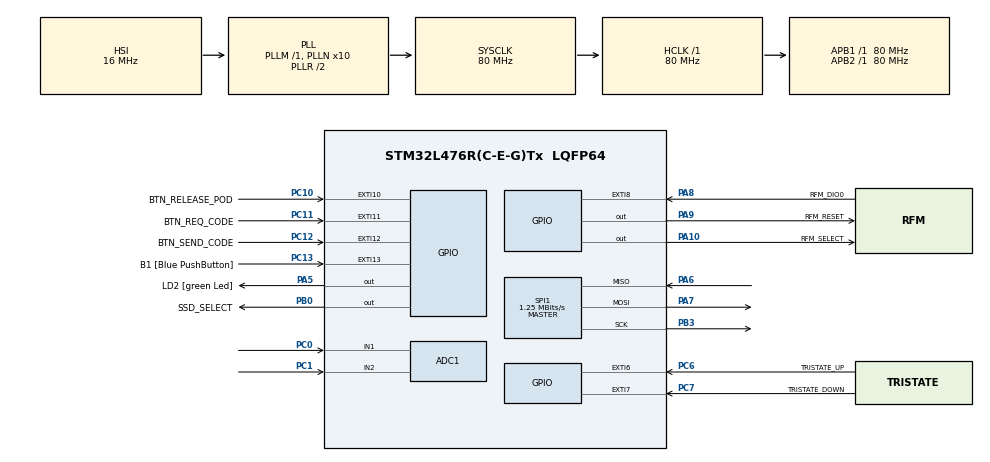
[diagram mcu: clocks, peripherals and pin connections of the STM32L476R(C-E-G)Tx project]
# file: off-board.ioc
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ADC1.Channel-0\#ChannelRegularConversion=ADC_CHANNEL_1
ADC1.Channel-1\#ChannelRegularConversion=ADC_CHANNEL_2
ADC1.ContinuousConvMode=DISABLE
ADC1.DMAContinuousRequests=DISABLE
ADC1.NbrOfConversion=2
ADC1.NbrOfConversionFlag=1
ADC1.OffsetNumber-0\#ChannelRegularConversion=ADC_OFFSET_NONE
ADC1.OffsetNumber-1\#ChannelRegularConversion=ADC_OFFSET_NONE
ADC1.Rank-0\#ChannelRegularConversion=1
ADC1.Rank-1\#ChannelRegularConversion=2
ADC1.SamplingTime-0\#ChannelRegularConversion=ADC_SAMPLETIME_2CYCLES_5
ADC1.SamplingTime-1\#ChannelRegularConversion=ADC_SAMPLETIME_2CYCLES_5
ADC1.master=1
Dma.ADC1.0.Direction=DMA_PERIPH_TO_MEMORY
Dma.ADC1.0.Instance=DMA1_Channel1
Dma.ADC1.0.MemDataAlignment=DMA_MDATAALIGN_HALFWORD
Dma.ADC1.0.MemInc=DMA_MINC_ENABLE
Dma.ADC1.0.Mode=DMA_NORMAL
Dma.ADC1.0.PeriphDataAlignment=DMA_PDATAALIGN_HALFWORD
Dma.ADC1.0.PeriphInc=DMA_PINC_DISABLE
Dma.ADC1.0.Priority=DMA_PRIORITY_HIGH
Dma.Request0=ADC1
Mcu.Family=STM32L4
Mcu.Name=STM32L476R(C-E-G)Tx
Mcu.Package=LQFP64
NVIC.ADC1_2_IRQn=true\:0\:0\:false\:false\:true\:true\:true\:true
NVIC.DMA1_Channel1_IRQn=true\:0\:0\:false\:false\:true\:false\:true\:true
NVIC.EXTI15_10_IRQn=true\:0\:0\:false\:false\:true\:true\:true\:true
NVIC.EXTI9_5_IRQn=true\:0\:0\:false\:false\:true\:true\:true\:true
NVIC.PriorityGroup=NVIC_PRIORITYGROUP_4
NVIC.SPI1_IRQn=true\:0\:0\:false\:false\:true\:true\:true\:true
NVIC.TIM6_DAC_IRQn=true\:0\:0\:false\:false\:true\:true\:true\:true
NVIC.TIM7_IRQn=true\:0\:0\:false\:false\:true\:true\:true\:true
PA10.GPIO_Label=RFM_SELECT
PA10.Signal=GPIO_Output
PA13\ (JTMS-SWDIO).Mode=Serial_Wire
PA13\ (JTMS-SWDIO).Signal=SYS_JTMS-SWDIO
PA14\ (JTCK-SWCLK).Mode=Serial_Wire
PA14\ (JTCK-SWCLK).Signal=SYS_JTCK-SWCLK
PA5.GPIO_Label=LD2 [green Led]
PA5.GPIO_ModeDefaultOutputPP=GPIO_MODE_OUTPUT_PP
PA5.GPIO_PuPd=GPIO_NOPULL
PA5.GPIO_Speed=GPIO_SPEED_FREQ_LOW
PA5.Signal=GPIO_Output
PA6.Mode=Full_Duplex_Master
PA6.Signal=SPI1_MISO
PA7.Mode=Full_Duplex_Master
PA7.Signal=SPI1_MOSI
PA8.GPIO_Label=RFM_DIO0
PA8.Signal=GPXTI8
PA9.GPIO_Label=RFM_RESET
PA9.Signal=GPIO_Output
PB0.GPIO_Label=SSD_SELECT
PB0.Signal=GPIO_Output
PB3\ (JTDO-TRACESWO).Mode=Full_Duplex_Master
PB3\ (JTDO-TRACESWO).Signal=SPI1_SCK
PC0.Signal=SharedAnalog_PC0
PC1.Signal=SharedAnalog_PC1
PC10.GPIO_Label=BTN_RELEASE_POD
PC10.GPIO_ModeDefaultEXTI=GPIO_MODE_IT_FALLING
PC10.GPIO_PuPd=GPIO_PULLDOWN
PC10.Signal=GPXTI10
PC11.GPIO_Label=BTN_REQ_CODE
PC11.GPIO_ModeDefaultEXTI=GPIO_MODE_IT_FALLING
PC11.GPIO_PuPd=GPIO_PULLDOWN
PC11.Signal=GPXTI11
PC12.GPIO_Label=BTN_SEND_CODE
PC12.GPIO_ModeDefaultEXTI=GPIO_MODE_IT_FALLING
PC12.GPIO_PuPd=GPIO_PULLDOWN
PC12.Signal=GPXTI12
PC13.GPIO_Label=B1 [Blue PushButton]
PC13.GPIO_ModeDefaultEXTI=GPIO_MODE_IT_FALLING
PC13.GPIO_PuPd=GPIO_NOPULL
PC13.Signal=GPXTI13
PC6.GPIO_Label=TRISTATE_UP
PC6.GPIO_PuPd=GPIO_PULLDOWN
PC6.Signal=GPXTI6
PC7.GPIO_Label=TRISTATE_DOWN
PC7.GPIO_PuPd=GPIO_PULLDOWN
PC7.Signal=GPXTI7
ProjectManager.HeapSize=0x200
ProjectManager.StackSize=0x400
ProjectManager.TargetToolchain=STM32CubeIDE
RCC.ADCFreq_Value=64000000
RCC.AHBFreq_Value=80000000
RCC.APB1Freq_Value=80000000
RCC.APB1TimFreq_Value=80000000
RCC.APB2Freq_Value=80000000
RCC.APB2TimFreq_Value=80000000
RCC.CortexFreq_Value=80000000
RCC.HCLKFreq_Value=80000000
RCC.HSE_VALUE=8000000
RCC.HSI_VALUE=16000000
RCC.LSE_VALUE=32768
RCC.MSI_VALUE=4000000
RCC.PLLN=10
RCC.PLLSourceVirtual=RCC_PLLSOURCE_HSI
RCC.PREFETCH_ENABLE=1
RCC.SYSCLKFreq_VALUE=80000000
RCC.SYSCLKSource=RCC_SYSCLKSOURCE_PLLCLK
RCC.USBFreq_Value=64000000
RCC.VCOOutputFreq_Value=160000000
SH.SharedAnalog_PC0.0=GPIO_Analog
SH.SharedAnalog_PC0.1=ADC1_IN1,IN1-Single-Ended
SH.SharedAnalog_PC1.0=GPIO_Analog
SH.SharedAnalog_PC1.1=ADC1_IN2,IN2-Single-Ended
SPI1.BaudRatePrescaler=SPI_BAUDRATEPRESCALER_64
SPI1.CalculateBaudRate=1.25 MBits/s
SPI1.DataSize=SPI_DATASIZE_8BIT
SPI1.Direction=SPI_DIRECTION_2LINES
SPI1.Mode=SPI_MODE_MASTER
SPI1.NSSPMode=SPI_NSS_PULSE_DISABLE
SPI1.VirtualType=VM_MASTER
TIM6.AutoReloadPreload=TIM_AUTORELOAD_PRELOAD_ENABLE
TIM6.Period=62499
TIM6.Prescaler=319
TIM7.AutoReloadPreload=TIM_AUTORELOAD_PRELOAD_ENABLE
TIM7.Period=49999
TIM7.Prescaler=159
VP_TIM6_VS_ClockSourceINT.Mode=Enable_Timer
VP_TIM7_VS_ClockSourceINT.Mode=Enable_Timer
board=NUCLEO-L476RG

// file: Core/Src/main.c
/* USER CODE BEGIN Header */
/**
  ******************************************************************************
  * @file           : main.c
  * @brief          : Main program body
  ******************************************************************************
  * @attention
  *
  * Copyright (c) 2024 STMicroelectronics.
  * All rights reserved.
  *
  * This software is licensed under terms that can be found in the LICENSE file
  * in the root directory of this software component.
  * If no LICENSE file comes with this software, it is provided AS-IS.
  *
  ******************************************************************************
  */
/* USER CODE END Header */
#include "main.h"

/* USER CODE BEGIN Includes */
#include "Custom/main.h"
/* USER CODE END Includes */

ADC_HandleTypeDef hadc1;
DMA_HandleTypeDef hdma_adc1;

SPI_HandleTypeDef hspi1;

TIM_HandleTypeDef htim6;
TIM_HandleTypeDef htim7;

void SystemClock_Config(void);
static void MX_GPIO_Init(void);
static void MX_DMA_Init(void);
static void MX_ADC1_Init(void);
static void MX_SPI1_Init(void);
static void MX_TIM7_Init(void);
static void MX_TIM6_Init(void);

int main(void)
{

  /* MCU Configuration--------------------------------------------------------*/

  /* Reset of all peripherals, Initializes the Flash interface and the Systick. */
  HAL_Init();

  /* Configure the system clock */
  SystemClock_Config();

  /* Initialize all configured peripherals */
  MX_GPIO_Init();
  MX_DMA_Init();
  MX_ADC1_Init();
  MX_SPI1_Init();
  MX_TIM7_Init();
  MX_TIM6_Init();
  /* USER CODE BEGIN 2 */
  setup();
  /* USER CODE END 2 */

  /* Infinite loop */
  /* USER CODE BEGIN WHILE */
  while (1)
  {
    loop();
    /* USER CODE END WHILE */

  }
}

void SystemClock_Config(void)
{
  RCC_OscInitTypeDef RCC_OscInitStruct = {0};
  RCC_ClkInitTypeDef RCC_ClkInitStruct = {0};

  /** Configure the main internal regulator output voltage
  */
  if (HAL_PWREx_ControlVoltageScaling(PWR_REGULATOR_VOLTAGE_SCALE1) != HAL_OK)
  {
    Error_Handler();
  }

  /** Initializes the RCC Oscillators according to the specified parameters
  * in the RCC_OscInitTypeDef structure.
  */
  RCC_OscInitStruct.OscillatorType = RCC_OSCILLATORTYPE_HSI;
  RCC_OscInitStruct.HSIState = RCC_HSI_ON;
  RCC_OscInitStruct.HSICalibrationValue = RCC_HSICALIBRATION_DEFAULT;
  RCC_OscInitStruct.PLL.PLLState = RCC_PLL_ON;
  RCC_OscInitStruct.PLL.PLLSource = RCC_PLLSOURCE_HSI;
  RCC_OscInitStruct.PLL.PLLM = 1;
  RCC_OscInitStruct.PLL.PLLN = 10;
  RCC_OscInitStruct.PLL.PLLP = RCC_PLLP_DIV7;
  RCC_OscInitStruct.PLL.PLLQ = RCC_PLLQ_DIV2;
  RCC_OscInitStruct.PLL.PLLR = RCC_PLLR_DIV2;
  if (HAL_RCC_OscConfig(&RCC_OscInitStruct) != HAL_OK)
  {
    Error_Handler();
  }

  /** Initializes the CPU, AHB and APB buses clocks
  */
  RCC_ClkInitStruct.ClockType = RCC_CLOCKTYPE_HCLK|RCC_CLOCKTYPE_SYSCLK
                              |RCC_CLOCKTYPE_PCLK1|RCC_CLOCKTYPE_PCLK2;
  RCC_ClkInitStruct.SYSCLKSource = RCC_SYSCLKSOURCE_PLLCLK;
  RCC_ClkInitStruct.AHBCLKDivider = RCC_SYSCLK_DIV1;
  RCC_ClkInitStruct.APB1CLKDivider = RCC_HCLK_DIV1;
  RCC_ClkInitStruct.APB2CLKDivider = RCC_HCLK_DIV1;

  if (HAL_RCC_ClockConfig(&RCC_ClkInitStruct, FLASH_LATENCY_4) != HAL_OK)
  {
    Error_Handler();
  }
}

static void MX_ADC1_Init(void)
{

  ADC_MultiModeTypeDef multimode = {0};
  ADC_ChannelConfTypeDef sConfig = {0};

  /** Common config
  */
  hadc1.Instance = ADC1;
  hadc1.Init.ClockPrescaler = ADC_CLOCK_ASYNC_DIV1;
  hadc1.Init.Resolution = ADC_RESOLUTION_12B;
  hadc1.Init.DataAlign = ADC_DATAALIGN_RIGHT;
  hadc1.Init.ScanConvMode = ADC_SCAN_ENABLE;
  hadc1.Init.EOCSelection = ADC_EOC_SINGLE_CONV;
  hadc1.Init.LowPowerAutoWait = DISABLE;
  hadc1.Init.ContinuousConvMode = DISABLE;
  hadc1.Init.NbrOfConversion = 2;
  hadc1.Init.DiscontinuousConvMode = DISABLE;
  hadc1.Init.ExternalTrigConv = ADC_SOFTWARE_START;
  hadc1.Init.ExternalTrigConvEdge = ADC_EXTERNALTRIGCONVEDGE_NONE;
  hadc1.Init.DMAContinuousRequests = DISABLE;
  hadc1.Init.Overrun = ADC_OVR_DATA_PRESERVED;
  hadc1.Init.OversamplingMode = DISABLE;
  if (HAL_ADC_Init(&hadc1) != HAL_OK)
  {
    Error_Handler();
  }

  /** Configure the ADC multi-mode
  */
  multimode.Mode = ADC_MODE_INDEPENDENT;
  if (HAL_ADCEx_MultiModeConfigChannel(&hadc1, &multimode) != HAL_OK)
  {
    Error_Handler();
  }

  /** Configure Regular Channel
  */
  sConfig.Channel = ADC_CHANNEL_1;
  sConfig.Rank = ADC_REGULAR_RANK_1;
  sConfig.SamplingTime = ADC_SAMPLETIME_2CYCLES_5;
  sConfig.SingleDiff = ADC_SINGLE_ENDED;
  sConfig.OffsetNumber = ADC_OFFSET_NONE;
  sConfig.Offset = 0;
  if (HAL_ADC_ConfigChannel(&hadc1, &sConfig) != HAL_OK)
  {
    Error_Handler();
  }

  /** Configure Regular Channel
  */
  sConfig.Channel = ADC_CHANNEL_2;
  sConfig.Rank = ADC_REGULAR_RANK_2;
  if (HAL_ADC_ConfigChannel(&hadc1, &sConfig) != HAL_OK)
  {
    Error_Handler();
  }

}

static void MX_SPI1_Init(void)
{

  /* SPI1 parameter configuration*/
  hspi1.Instance = SPI1;
  hspi1.Init.Mode = SPI_MODE_MASTER;
  hspi1.Init.Direction = SPI_DIRECTION_2LINES;
  hspi1.Init.DataSize = SPI_DATASIZE_8BIT;
  hspi1.Init.CLKPolarity = SPI_POLARITY_LOW;
  hspi1.Init.CLKPhase = SPI_PHASE_1EDGE;
  hspi1.Init.NSS = SPI_NSS_SOFT;
  hspi1.Init.BaudRatePrescaler = SPI_BAUDRATEPRESCALER_64;
  hspi1.Init.FirstBit = SPI_FIRSTBIT_MSB;
  hspi1.Init.TIMode = SPI_TIMODE_DISABLE;
  hspi1.Init.CRCCalculation = SPI_CRCCALCULATION_DISABLE;
  hspi1.Init.CRCPolynomial = 7;
  hspi1.Init.CRCLength = SPI_CRC_LENGTH_DATASIZE;
  hspi1.Init.NSSPMode = SPI_NSS_PULSE_DISABLE;
  if (HAL_SPI_Init(&hspi1) != HAL_OK)
  {
    Error_Handler();
  }

}

static void MX_TIM6_Init(void)
{

  TIM_MasterConfigTypeDef sMasterConfig = {0};

  htim6.Instance = TIM6;
  htim6.Init.Prescaler = 319;
  htim6.Init.CounterMode = TIM_COUNTERMODE_UP;
  htim6.Init.Period = 62499;
  htim6.Init.AutoReloadPreload = TIM_AUTORELOAD_PRELOAD_ENABLE;
  if (HAL_TIM_Base_Init(&htim6) != HAL_OK)
  {
    Error_Handler();
  }
  sMasterConfig.MasterOutputTrigger = TIM_TRGO_RESET;
  sMasterConfig.MasterSlaveMode = TIM_MASTERSLAVEMODE_DISABLE;
  if (HAL_TIMEx_MasterConfigSynchronization(&htim6, &sMasterConfig) != HAL_OK)
  {
    Error_Handler();
  }

}

static void MX_TIM7_Init(void)
{

  TIM_MasterConfigTypeDef sMasterConfig = {0};

  htim7.Instance = TIM7;
  htim7.Init.Prescaler = 159;
  htim7.Init.CounterMode = TIM_COUNTERMODE_UP;
  htim7.Init.Period = 49999;
  htim7.Init.AutoReloadPreload = TIM_AUTORELOAD_PRELOAD_ENABLE;
  if (HAL_TIM_Base_Init(&htim7) != HAL_OK)
  {
    Error_Handler();
  }
  sMasterConfig.MasterOutputTrigger = TIM_TRGO_RESET;
  sMasterConfig.MasterSlaveMode = TIM_MASTERSLAVEMODE_DISABLE;
  if (HAL_TIMEx_MasterConfigSynchronization(&htim7, &sMasterConfig) != HAL_OK)
  {
    Error_Handler();
  }

}

static void MX_DMA_Init(void)
{

  /* DMA controller clock enable */
  __HAL_RCC_DMA1_CLK_ENABLE();

  /* DMA interrupt init */
  /* DMA1_Channel1_IRQn interrupt configuration */
  HAL_NVIC_SetPriority(DMA1_Channel1_IRQn, 0, 0);
  HAL_NVIC_EnableIRQ(DMA1_Channel1_IRQn);

}

static void MX_GPIO_Init(void)
{
  GPIO_InitTypeDef GPIO_InitStruct = {0};

  /* GPIO Ports Clock Enable */
  __HAL_RCC_GPIOC_CLK_ENABLE();
  __HAL_RCC_GPIOA_CLK_ENABLE();
  __HAL_RCC_GPIOB_CLK_ENABLE();

  /*Configure GPIO pin Output Level */
  HAL_GPIO_WritePin(GPIOA, LD2_Pin|RFM_RESET_Pin|RFM_SELECT_Pin, GPIO_PIN_RESET);

  /*Configure GPIO pin Output Level */
  HAL_GPIO_WritePin(SSD_SELECT_GPIO_Port, SSD_SELECT_Pin, GPIO_PIN_RESET);

  /*Configure GPIO pin : B1_Pin */
  GPIO_InitStruct.Pin = B1_Pin;
  GPIO_InitStruct.Mode = GPIO_MODE_IT_FALLING;
  GPIO_InitStruct.Pull = GPIO_NOPULL;
  HAL_GPIO_Init(B1_GPIO_Port, &GPIO_InitStruct);

  /*Configure GPIO pins : LD2_Pin RFM_RESET_Pin RFM_SELECT_Pin */
  GPIO_InitStruct.Pin = LD2_Pin|RFM_RESET_Pin|RFM_SELECT_Pin;
  GPIO_InitStruct.Mode = GPIO_MODE_OUTPUT_PP;
  GPIO_InitStruct.Pull = GPIO_NOPULL;
  GPIO_InitStruct.Speed = GPIO_SPEED_FREQ_LOW;
  HAL_GPIO_Init(GPIOA, &GPIO_InitStruct);

  /*Configure GPIO pin : SSD_SELECT_Pin */
  GPIO_InitStruct.Pin = SSD_SELECT_Pin;
  GPIO_InitStruct.Mode = GPIO_MODE_OUTPUT_PP;
  GPIO_InitStruct.Pull = GPIO_NOPULL;
  GPIO_InitStruct.Speed = GPIO_SPEED_FREQ_LOW;
  HAL_GPIO_Init(SSD_SELECT_GPIO_Port, &GPIO_InitStruct);

  /*Configure GPIO pins : TRISTATE_UP_Pin TRISTATE_DOWN_Pin */
  GPIO_InitStruct.Pin = TRISTATE_UP_Pin|TRISTATE_DOWN_Pin;
  GPIO_InitStruct.Mode = GPIO_MODE_IT_RISING;
  GPIO_InitStruct.Pull = GPIO_PULLDOWN;
  HAL_GPIO_Init(GPIOC, &GPIO_InitStruct);

  /*Configure GPIO pin : RFM_DIO0_Pin */
  GPIO_InitStruct.Pin = RFM_DIO0_Pin;
  GPIO_InitStruct.Mode = GPIO_MODE_IT_RISING;
  GPIO_InitStruct.Pull = GPIO_NOPULL;
  HAL_GPIO_Init(RFM_DIO0_GPIO_Port, &GPIO_InitStruct);

  /*Configure GPIO pins : BTN_RELEASE_POD_Pin BTN_REQ_CODE_Pin BTN_SEND_CODE_Pin */
  GPIO_InitStruct.Pin = BTN_RELEASE_POD_Pin|BTN_REQ_CODE_Pin|BTN_SEND_CODE_Pin;
  GPIO_InitStruct.Mode = GPIO_MODE_IT_FALLING;
  GPIO_InitStruct.Pull = GPIO_PULLDOWN;
  HAL_GPIO_Init(GPIOC, &GPIO_InitStruct);

  /* EXTI interrupt init*/
  HAL_NVIC_SetPriority(EXTI9_5_IRQn, 0, 0);
  HAL_NVIC_EnableIRQ(EXTI9_5_IRQn);

  HAL_NVIC_SetPriority(EXTI15_10_IRQn, 0, 0);
  HAL_NVIC_EnableIRQ(EXTI15_10_IRQn);

}

void Error_Handler(void)
{
  __disable_irq();
  while (1)
  {
  }
}
